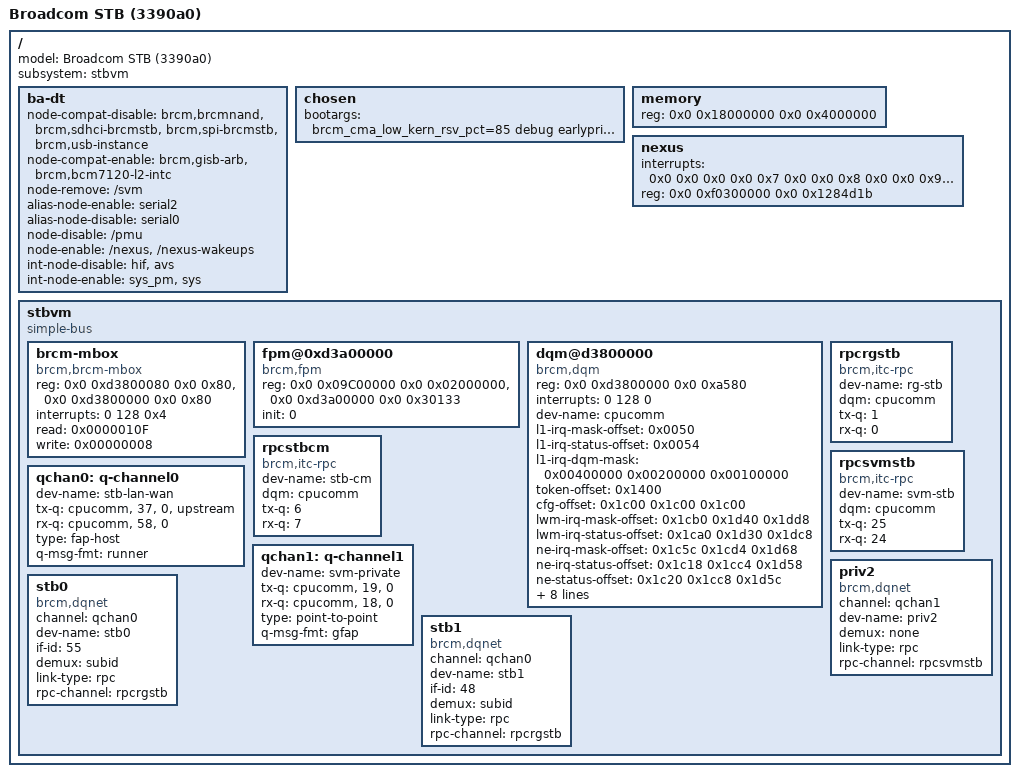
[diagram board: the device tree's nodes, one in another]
/dts-v1/;

/ {
	model = "Broadcom STB (3390a0)";
	subsystem = "stbvm";
	#address-cells = <0x2>;
	#size-cells = <0x2>;

	/* This node will "tweak" the device tree provided by boot loader and passed
	* down via SVM.
	* Disabled nodes will still be present, but associated drivers will not load
	* and resources will not be provided via hypervisor
	*
	* Disabled via compatible string:
	*	brcmnand - NAND, used by SVM
	*	sdhci-brcmstb - SDHCI, used by SVM
	*	spi-brcmstb - SPI.. TBD
	*	usb-instance - USB, used by SVM and RG
	* Enabled via compatible string:
	*	gisb-arb - GISB driver... TBD?
	*	brcm,bcm7120-l2-intc - Not used, TBD?
	* Removed by node name:
	*	svm - all "custom" svm device tree information
	* Enabled via alias name:
	*	serial2 - UARTC for STB
	* Disabled via alias name:
	*	serial0 - SVM serial port
	* Disabled by node name:
	*	pmu - pmu
	* Enabled by node name:
	*	nexus - nexus node from bolt
	*	nexus-wakeups - nexus node from bolt, needed?
	* Disabled L2 interrupt driver:
	*	hif - Used for NAND w/ SVM
	* Enabled L2 interrupt driver:
	*	sys_pm - Used by waketimer and nexus-wakeups... TBD?
	*	sys - Used by gisb-arb... TBD?
	*/
	ba-dt {
		node-compat-disable="brcm,brcmnand", "brcm,sdhci-brcmstb", "brcm,spi-brcmstb", "brcm,usb-instance";
		node-compat-enable="brcm,gisb-arb", "brcm,bcm7120-l2-intc";
		node-remove = "/svm";
		alias-node-enable = "serial2";
		alias-node-disable = "serial0";
		node-disable = "/pmu";
		node-enable = "/nexus", "/nexus-wakeups";
		int-node-disable = "hif", "avs";
		int-node-enable = "sys_pm", "sys";
	};

	chosen {
		//bootargs="brcm_cma_kern_rsv=239075328 debug ubi.mtd=vf0 root=ubi0:rootfs rootfstype=ubifs";
		//bootargs="brcm_cma_kern_rsv=239075328 debug earlyprintk";
		bootargs="brcm_cma_low_kern_rsv_pct=85 debug earlyprintk";

	};

	memory {
		reg = <0x0 0x18000000 0x0 0x4000000>;
	};

	/* Although the nexus node can largely be taken from bolt, there are some
	* customizations required to work with hypervisor, "reg" and "interrupts"
	* must be added to existing nodes */
	nexus {
		interrupts = <0x0 0x0 0x0 0x0 0x7 0x0 0x0 0x8 0x0 0x0 0x9 0x0 0x0 0xa 0x0 0x0 0xb 0x0 0x0 0xc 0x0 0x0 0xd 0x0 0x0 0xe 0x0 0x0 0xf 0x0 0x0 0x10 0x0 0x0 0x13 0x0 0x0 0x14 0x0 0x0 0x15 0x0 0x0 0x16 0x0 0x0 0x17 0x0 0x0 0x3b 0x0 0x0 0x3c 0x0 0x0 0x3d 0x0 0x0 0x3e 0x0 0x0 0x3f 0x0 0x0 0x40 0x0 0x0 0x42 0x0 0x0 0x43 0x0 0x0 0x44 0x0 0x0 0x45 0x0 0x0 0x46 0x0 0x0 0x47 0x0 0x0 0x49 0x0 0x0 0x4a 0x0 0x0 0x4b 0x0 0x0 0x57 0x0 0x0 0x58 0x0 0x0 0x59 0x0 0x0 0x5a 0x0 0x0 0x5b 0x0 0x0 0x5c 0x0 0x0 0x5f 0x0 0x0 0x60 0x0 0x0 0x61 0x0 0x0 0x62 0x0 0x0 0x63 0x0 0x0 0x64 0x0 0x0 0x68 0x0>;
		//reg = <0x0 0xf0300000 0x0 0x00ffffff 0x0 0xf0a00000 0x0 0x00b84d1b>;
		reg = <0x0 0xf0300000 0x0 0x1284d1b>;
	};

	stbvm {
		compatible = "simple-bus";
		#address-cells = <0x2>;
		#size-cells = <0x2>;
		ranges;

		brcm-mbox {
			compatible = "brcm,brcm-mbox";
			reg = <0x0 0xd3800080 0x0 0x80>, //MBOX_CPUC
			      <0x0 0xd3800000 0x0 0x80>; //CPU_COMM_REGS_CPUC
			interrupts = <0 128 0x4>;
			read = < 0x0000010F >; /* 0,1,2,3,8 */
			write = < 0x00000008 >; /* 3 */
		};

		fpm@0xd3a00000 {
			compatible = "brcm,fpm";
			reg = <0x0 0x09C00000 0x0 0x02000000>,	/* Free Pool 0	*/
			      <0x0 0xd3a00000 0x0 0x30133>;	/* Registers	*/
//			      <0x0 0x86000000 0x0 0x02000000>;	/* Free Pool 1	*/
//			      <0x0 0x00000000 0x0 0x0>,		/* Free Pool 1	*/
//			      <0x0 0xd7e00000 0x0 0x1000>,	/* UBUS capture engines 0 */
//			      <0x0 0xd3e00000 0x0 0x1000>;	/* UBUS capture engines 1 */
			init = <0>;
		};

		dqm@d3800000 {
			compatible = "brcm,dqm";
			reg = <0x0 0xd3800000 0x0 0xa580>;
			interrupts = <0 128 0>;

			dev-name = "cpucomm";

			l1-irq-mask-offset	= <0x0050>;
			l1-irq-status-offset	= <0x0054>;
			l1-irq-dqm-mask		= <0x00400000 0x00200000 0x00100000>;
			token-offset		= <0x1400>;

			cfg-offset		= <0x1c00 0x1c00 0x1c00>;
			lwm-irq-mask-offset	= <0x1cb0 0x1d40 0x1dd8>;
			lwm-irq-status-offset	= <0x1ca0 0x1d30 0x1dc8>;
			ne-irq-mask-offset	= <0x1c5c 0x1cd4 0x1d68>;
			ne-irq-status-offset	= <0x1c18 0x1cc4 0x1d58>;
			ne-status-offset	= <0x1c20 0x1cc8 0x1d5c>;
			fpm-alloc-offset	= <0x1df0 0x1df0 0x1df0>;	/* bug in 3390a0 requires write to prior reg */

			q-ctl-base-offset	= <0x8000 0x8400 0x8800>;
			q-data-base-offset	= <0x9000 0x9400 0x9800>;
			q-status-base-offset	= <0x7400 0x7480 0x7500>;
			q-mib-base-offset       = <0xa000 0xa200 0xa400>;

			q-count			= <96>;
			cfg-qsm			= <0>;
			qsm-size		= <0x3000>;
		};

		rpcrgstb: rpcrgstb {
			compatible = "brcm,itc-rpc";
			dev-name = "rg-stb";
			dqm = "cpucomm";
			tx-q = <1>;
			rx-q = <0>;
		};

		rpcstbcm: rpcstbcm {
			compatible = "brcm,itc-rpc";
			dev-name = "stb-cm";
			dqm = "cpucomm";
			tx-q = <6>;
			rx-q = <7>;
		};

		rpcsvmstb: rpcsvmstb {
			compatible = "brcm,itc-rpc";
			dev-name = "svm-stb";
			dqm = "cpucomm";
			tx-q = <25>;
			rx-q = <24>;
		};
/*
		vflashclient {
			compatible = "brcm,brcm-vflashclient";
			reg = <0x0 0x0da00000 0x0 0x400000>;
			client_id = <1>;
			rpc_channel = <&rpcsvmstb>;
		};
*/
		qchan0: q-channel0 {
			dev-name = "stb-lan-wan";

			#tx-q-cells = <4>;
			/*	DQM device,	Q#,	Priority	US/DS					*/
			tx-q =	"cpucomm",	"37",	"0",		"upstream";	/* STB upstream forward	*/
			#rx-q-cells = <3>;
			/*	DQM device,	Q#,	Priority						*/
			rx-q =	"cpucomm",	"58",	"0";				/* Runner-->STB		*/

			type = "fap-host";
			q-msg-fmt = "runner";
		};

		qchan1: q-channel1 {
			dev-name = "svm-private";

			#tx-q-cells = <3>;
			/*	DQM device,	Q#,	Priority	US/DS				*/
			tx-q =	"cpucomm",	"19",	"0";				/* STB-->SVM	*/
			#rx-q-cells = <3>;
			/*	DQM device,	Q#,	Priority					*/
			rx-q =	"cpucomm",	"18",	"0";				/* SVM-->STB	*/

			type = "point-to-point";
			q-msg-fmt = "gfap";
		};

		priv2 { /* STB <--> SVM private */
			compatible = "brcm,dqnet";
			channel = <&qchan1>;
			dev-name = "priv2";
			demux = "none";
			link-type = "rpc";
			rpc-channel = <&rpcsvmstb>;
		};

		stb0 { /* STB routed */
			compatible = "brcm,dqnet";
			channel = <&qchan0>;
			dev-name = "stb0";
			if-id = <55>;		/* rdpa_if_ssid14 */
			demux = "subid";
			link-type = "rpc";
			rpc-channel = <&rpcrgstb>;
		};

		stb1 { /* STB bridged */
			compatible = "brcm,dqnet";
			channel = <&qchan0>;
			dev-name = "stb1";
			if-id = <48>;		/* rdpa_if_ssid15 */
			demux = "subid";
			link-type = "rpc";
			rpc-channel = <&rpcrgstb>;
		};
	};
};
